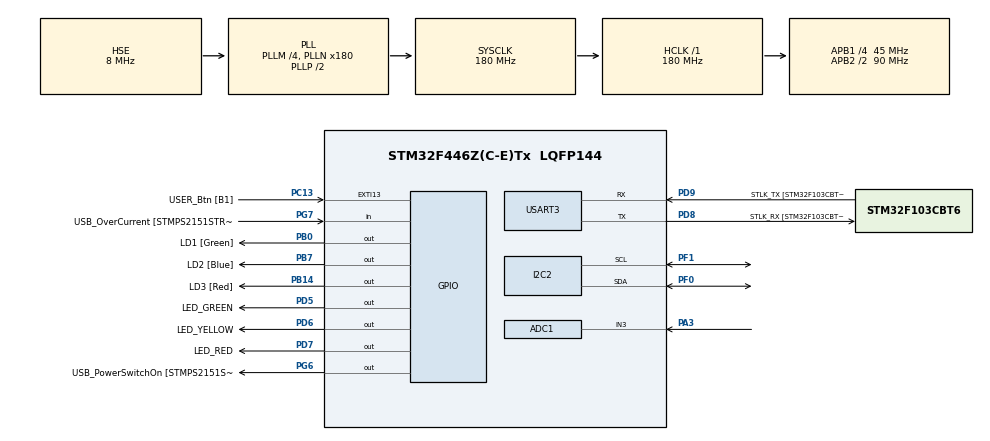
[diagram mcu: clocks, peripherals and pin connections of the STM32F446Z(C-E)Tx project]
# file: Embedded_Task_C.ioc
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ADC1.Channel-2\#ChannelRegularConversion=ADC_CHANNEL_3
ADC1.ClockPrescaler=ADC_CLOCK_SYNC_PCLK_DIV8
ADC1.ExternalTrigConv=ADC_EXTERNALTRIGCONV_T2_TRGO
ADC1.InjNumberOfConversion=0
ADC1.NbrOfConversion=1
ADC1.NbrOfConversionFlag=1
ADC1.Rank-2\#ChannelRegularConversion=1
ADC1.SamplingTime-2\#ChannelRegularConversion=ADC_SAMPLETIME_480CYCLES
ADC1.master=1
Mcu.Family=STM32F4
Mcu.Name=STM32F446Z(C-E)Tx
Mcu.Package=LQFP144
NVIC.ADC_IRQn=true\:0\:0\:false\:false\:true\:true\:true\:true
NVIC.PriorityGroup=NVIC_PRIORITYGROUP_4
NVIC.USART3_IRQn=true\:14\:0\:true\:false\:true\:true\:true\:true
PA10.GPIO_Label=USB_ID
PA10.Signal=USB_OTG_FS_ID
PA11.GPIO_Label=USB_DM
PA11.Signal=USB_OTG_FS_DM
PA12.GPIO_Label=USB_DP
PA12.Signal=USB_OTG_FS_DP
PA13.GPIO_Label=TMS
PA13.Mode=Serial_Wire
PA13.Signal=SYS_JTMS-SWDIO
PA14.GPIO_Label=TCK
PA14.Mode=Serial_Wire
PA14.Signal=SYS_JTCK-SWCLK
PA3.Signal=ADCx_IN3
PA8.GPIO_Label=USB_SOF [TP1]
PA8.Signal=USB_OTG_FS_SOF
PA9.GPIO_Label=USB_VBUS
PA9.Signal=USB_OTG_FS_VBUS
PB0.GPIO_Label=LD1 [Green]
PB0.Signal=GPIO_Output
PB14.GPIO_Label=LD3 [Red]
PB14.Signal=GPIO_Output
PB7.GPIO_Label=LD2 [Blue]
PB7.Signal=GPIO_Output
PC13.GPIO_Label=USER_Btn [B1]
PC13.Signal=GPXTI13
PC14-OSC32_IN.Mode=LSE-External-Oscillator
PC14-OSC32_IN.Signal=RCC_OSC32_IN
PC15-OSC32_OUT.Mode=LSE-External-Oscillator
PC15-OSC32_OUT.Signal=RCC_OSC32_OUT
PD5.GPIO_Label=LED_GREEN
PD5.Signal=GPIO_Output
PD6.GPIO_Label=LED_YELLOW
PD6.Signal=GPIO_Output
PD7.GPIO_Label=LED_RED
PD7.Signal=GPIO_Output
PD8.GPIO_Label=STLK_RX [STM32F103CBT6_PA3]
PD8.Mode=Asynchronous
PD8.Signal=USART3_TX
PD9.GPIO_Label=STLK_TX [STM32F103CBT6_PA2]
PD9.Mode=Asynchronous
PD9.Signal=USART3_RX
PF0.Mode=I2C
PF0.Signal=I2C2_SDA
PF1.Mode=I2C
PF1.Signal=I2C2_SCL
PG6.GPIO_Label=USB_PowerSwitchOn [STMPS2151STR_EN]
PG6.Signal=GPIO_Output
PG7.GPIO_Label=USB_OverCurrent [STMPS2151STR_FAULT]
PG7.Signal=GPIO_Input
PH0-OSC_IN.GPIO_Label=MCO [STM32F103CBT6_PA8]
PH0-OSC_IN.Mode=HSE-External-Clock-Source
PH0-OSC_IN.Signal=RCC_OSC_IN
PH1-OSC_OUT.Mode=HSE-External-Clock-Source
PH1-OSC_OUT.Signal=RCC_OSC_OUT
ProjectManager.HeapSize=0x200
ProjectManager.StackSize=0x400
ProjectManager.TargetToolchain=STM32CubeIDE
RCC.48MHZClocksFreq_Value=24000000
RCC.AHBFreq_Value=180000000
RCC.APB1CLKDivider=RCC_HCLK_DIV4
RCC.APB1Freq_Value=45000000
RCC.APB1TimFreq_Value=90000000
RCC.APB2CLKDivider=RCC_HCLK_DIV2
RCC.APB2Freq_Value=90000000
RCC.APB2TimFreq_Value=180000000
RCC.CortexFreq_Value=180000000
RCC.HCLKFreq_Value=180000000
RCC.HSE_VALUE=8000000
RCC.HSI_VALUE=16000000
RCC.PLLM=4
RCC.PLLMUL=RCC_PLL_MUL9
RCC.PLLN=180
RCC.PLLQ=7
RCC.PLLSourceVirtual=RCC_PLLSOURCE_HSE
RCC.PRESCALERUSB=RCC_USBCLKSOURCE_PLL_DIV1_5
RCC.SYSCLKFreq_VALUE=180000000
RCC.SYSCLKSource=RCC_SYSCLKSOURCE_PLLCLK
RCC.SYSCLKSourceVirtual=RCC_SYSCLKSOURCE_PLLCLK
RCC.USBFreq_Value=51428571.428571425
RCC.VCOOutputFreq_Value=360000000
SH.ADCx_IN3.0=ADC1_IN3,IN3
TIM2.Channel-PWM\ Generation1\ No\ Output=TIM_CHANNEL_1
TIM2.Period=8999
TIM2.Prescaler=0
TIM2.TIM_MasterOutputTrigger=TIM_TRGO_UPDATE
USART3.VirtualMode=VM_ASYNC
VP_TIM2_VS_no_output1.Mode=PWM Generation1 No Output
board=NUCLEO-F446ZE

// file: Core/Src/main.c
/* USER CODE BEGIN Header */
/**
  ******************************************************************************
  * @file           : main.c
  * @brief          : Main program body
  ******************************************************************************
  * @attention
  *
  * Copyright (c) 2025 STMicroelectronics.
  * All rights reserved.
  *
  * This software is licensed under terms that can be found in the LICENSE file
  * in the root directory of this software component.
  * If no LICENSE file comes with this software, it is provided AS-IS.
  *
  ******************************************************************************
  */
/* USER CODE END Header */
#include "main.h"

/* USER CODE BEGIN Includes */
#include "retarget.h"
#include "system.h"
/* USER CODE END Includes */

ADC_HandleTypeDef hadc1;

I2C_HandleTypeDef hi2c2;

TIM_HandleTypeDef htim2;

UART_HandleTypeDef huart3;

void SystemClock_Config(void);
static void MX_GPIO_Init(void);
static void MX_USART3_UART_Init(void);
static void MX_ADC1_Init(void);
static void MX_TIM2_Init(void);
static void MX_I2C2_Init(void);

int main(void)
{

  /* MCU Configuration--------------------------------------------------------*/

  /* Reset of all peripherals, Initializes the Flash interface and the Systick. */
  HAL_Init();

  /* Configure the system clock */
  SystemClock_Config();

  /* Initialize all configured peripherals */
  MX_GPIO_Init();
  MX_USART3_UART_Init();
  MX_ADC1_Init();
  MX_TIM2_Init();
  MX_I2C2_Init();
  /* USER CODE BEGIN 2 */

  RetargetInit(&huart3);

  HAL_Delay(1000);

  if (!SYSTEM_Init()) {
    //initialisation failed: wait a little to allow debug printouts to finish, then halt
    printf("*** System initialisation failed!\n");
    HAL_Delay(100);
    Error_Handler();
  }

  /* USER CODE END 2 */

  /* Infinite loop */
  while (1)
  {

    /* USER CODE BEGIN 3 */

    //perform system loop updates
    SYSTEM_LoopUpdate();
  }
  /* USER CODE END 3 */
}

void SystemClock_Config(void)
{
  RCC_OscInitTypeDef RCC_OscInitStruct = {0};
  RCC_ClkInitTypeDef RCC_ClkInitStruct = {0};

  /** Configure the main internal regulator output voltage
  */
  __HAL_RCC_PWR_CLK_ENABLE();
  __HAL_PWR_VOLTAGESCALING_CONFIG(PWR_REGULATOR_VOLTAGE_SCALE1);

  /** Initializes the RCC Oscillators according to the specified parameters
  * in the RCC_OscInitTypeDef structure.
  */
  RCC_OscInitStruct.OscillatorType = RCC_OSCILLATORTYPE_HSE;
  RCC_OscInitStruct.HSEState = RCC_HSE_BYPASS;
  RCC_OscInitStruct.PLL.PLLState = RCC_PLL_ON;
  RCC_OscInitStruct.PLL.PLLSource = RCC_PLLSOURCE_HSE;
  RCC_OscInitStruct.PLL.PLLM = 4;
  RCC_OscInitStruct.PLL.PLLN = 180;
  RCC_OscInitStruct.PLL.PLLP = RCC_PLLP_DIV2;
  RCC_OscInitStruct.PLL.PLLQ = 7;
  RCC_OscInitStruct.PLL.PLLR = 2;
  if (HAL_RCC_OscConfig(&RCC_OscInitStruct) != HAL_OK)
  {
    Error_Handler();
  }

  /** Activate the Over-Drive mode
  */
  if (HAL_PWREx_EnableOverDrive() != HAL_OK)
  {
    Error_Handler();
  }

  /** Initializes the CPU, AHB and APB buses clocks
  */
  RCC_ClkInitStruct.ClockType = RCC_CLOCKTYPE_HCLK|RCC_CLOCKTYPE_SYSCLK
                              |RCC_CLOCKTYPE_PCLK1|RCC_CLOCKTYPE_PCLK2;
  RCC_ClkInitStruct.SYSCLKSource = RCC_SYSCLKSOURCE_PLLCLK;
  RCC_ClkInitStruct.AHBCLKDivider = RCC_SYSCLK_DIV1;
  RCC_ClkInitStruct.APB1CLKDivider = RCC_HCLK_DIV4;
  RCC_ClkInitStruct.APB2CLKDivider = RCC_HCLK_DIV2;

  if (HAL_RCC_ClockConfig(&RCC_ClkInitStruct, FLASH_LATENCY_5) != HAL_OK)
  {
    Error_Handler();
  }
}

static void MX_ADC1_Init(void)
{

  ADC_ChannelConfTypeDef sConfig = {0};

  /** Configure the global features of the ADC (Clock, Resolution, Data Alignment and number of conversion)
  */
  hadc1.Instance = ADC1;
  hadc1.Init.ClockPrescaler = ADC_CLOCK_SYNC_PCLK_DIV8;
  hadc1.Init.Resolution = ADC_RESOLUTION_12B;
  hadc1.Init.ScanConvMode = DISABLE;
  hadc1.Init.ContinuousConvMode = DISABLE;
  hadc1.Init.DiscontinuousConvMode = DISABLE;
  hadc1.Init.ExternalTrigConvEdge = ADC_EXTERNALTRIGCONVEDGE_RISING;
  hadc1.Init.ExternalTrigConv = ADC_EXTERNALTRIGCONV_T2_TRGO;
  hadc1.Init.DataAlign = ADC_DATAALIGN_RIGHT;
  hadc1.Init.NbrOfConversion = 1;
  hadc1.Init.DMAContinuousRequests = DISABLE;
  hadc1.Init.EOCSelection = ADC_EOC_SINGLE_CONV;
  if (HAL_ADC_Init(&hadc1) != HAL_OK)
  {
    Error_Handler();
  }

  /** Configure for the selected ADC regular channel its corresponding rank in the sequencer and its sample time.
  */
  sConfig.Channel = ADC_CHANNEL_3;
  sConfig.Rank = 1;
  sConfig.SamplingTime = ADC_SAMPLETIME_480CYCLES;
  if (HAL_ADC_ConfigChannel(&hadc1, &sConfig) != HAL_OK)
  {
    Error_Handler();
  }

}

static void MX_I2C2_Init(void)
{

  hi2c2.Instance = I2C2;
  hi2c2.Init.ClockSpeed = 100000;
  hi2c2.Init.DutyCycle = I2C_DUTYCYCLE_2;
  hi2c2.Init.OwnAddress1 = 0;
  hi2c2.Init.AddressingMode = I2C_ADDRESSINGMODE_7BIT;
  hi2c2.Init.DualAddressMode = I2C_DUALADDRESS_DISABLE;
  hi2c2.Init.OwnAddress2 = 0;
  hi2c2.Init.GeneralCallMode = I2C_GENERALCALL_DISABLE;
  hi2c2.Init.NoStretchMode = I2C_NOSTRETCH_DISABLE;
  if (HAL_I2C_Init(&hi2c2) != HAL_OK)
  {
    Error_Handler();
  }

}

static void MX_TIM2_Init(void)
{

  TIM_MasterConfigTypeDef sMasterConfig = {0};
  TIM_OC_InitTypeDef sConfigOC = {0};

  htim2.Instance = TIM2;
  htim2.Init.Prescaler = 0;
  htim2.Init.CounterMode = TIM_COUNTERMODE_UP;
  htim2.Init.Period = 8999;
  htim2.Init.ClockDivision = TIM_CLOCKDIVISION_DIV1;
  htim2.Init.AutoReloadPreload = TIM_AUTORELOAD_PRELOAD_DISABLE;
  if (HAL_TIM_PWM_Init(&htim2) != HAL_OK)
  {
    Error_Handler();
  }
  sMasterConfig.MasterOutputTrigger = TIM_TRGO_UPDATE;
  sMasterConfig.MasterSlaveMode = TIM_MASTERSLAVEMODE_DISABLE;
  if (HAL_TIMEx_MasterConfigSynchronization(&htim2, &sMasterConfig) != HAL_OK)
  {
    Error_Handler();
  }
  sConfigOC.OCMode = TIM_OCMODE_PWM1;
  sConfigOC.Pulse = 0;
  sConfigOC.OCPolarity = TIM_OCPOLARITY_HIGH;
  sConfigOC.OCFastMode = TIM_OCFAST_DISABLE;
  if (HAL_TIM_PWM_ConfigChannel(&htim2, &sConfigOC, TIM_CHANNEL_1) != HAL_OK)
  {
    Error_Handler();
  }

}

static void MX_USART3_UART_Init(void)
{

  huart3.Instance = USART3;
  huart3.Init.BaudRate = 115200;
  huart3.Init.WordLength = UART_WORDLENGTH_8B;
  huart3.Init.StopBits = UART_STOPBITS_1;
  huart3.Init.Parity = UART_PARITY_NONE;
  huart3.Init.Mode = UART_MODE_TX_RX;
  huart3.Init.HwFlowCtl = UART_HWCONTROL_NONE;
  huart3.Init.OverSampling = UART_OVERSAMPLING_16;
  if (HAL_UART_Init(&huart3) != HAL_OK)
  {
    Error_Handler();
  }

}

static void MX_GPIO_Init(void)
{
  GPIO_InitTypeDef GPIO_InitStruct = {0};

  /* GPIO Ports Clock Enable */
  __HAL_RCC_GPIOC_CLK_ENABLE();
  __HAL_RCC_GPIOF_CLK_ENABLE();
  __HAL_RCC_GPIOH_CLK_ENABLE();
  __HAL_RCC_GPIOA_CLK_ENABLE();
  __HAL_RCC_GPIOB_CLK_ENABLE();
  __HAL_RCC_GPIOD_CLK_ENABLE();
  __HAL_RCC_GPIOG_CLK_ENABLE();

  /*Configure GPIO pin Output Level */
  HAL_GPIO_WritePin(GPIOB, LD1_Pin|LD3_Pin|LD2_Pin, GPIO_PIN_RESET);

  /*Configure GPIO pin Output Level */
  HAL_GPIO_WritePin(USB_PowerSwitchOn_GPIO_Port, USB_PowerSwitchOn_Pin, GPIO_PIN_RESET);

  /*Configure GPIO pin Output Level */
  HAL_GPIO_WritePin(GPIOD, LED_GREEN_Pin|LED_YELLOW_Pin|LED_RED_Pin, GPIO_PIN_RESET);

  /*Configure GPIO pin : USER_Btn_Pin */
  GPIO_InitStruct.Pin = USER_Btn_Pin;
  GPIO_InitStruct.Mode = GPIO_MODE_IT_RISING;
  GPIO_InitStruct.Pull = GPIO_NOPULL;
  HAL_GPIO_Init(USER_Btn_GPIO_Port, &GPIO_InitStruct);

  /*Configure GPIO pins : LD1_Pin LD3_Pin LD2_Pin */
  GPIO_InitStruct.Pin = LD1_Pin|LD3_Pin|LD2_Pin;
  GPIO_InitStruct.Mode = GPIO_MODE_OUTPUT_PP;
  GPIO_InitStruct.Pull = GPIO_NOPULL;
  GPIO_InitStruct.Speed = GPIO_SPEED_FREQ_LOW;
  HAL_GPIO_Init(GPIOB, &GPIO_InitStruct);

  /*Configure GPIO pin : USB_PowerSwitchOn_Pin */
  GPIO_InitStruct.Pin = USB_PowerSwitchOn_Pin;
  GPIO_InitStruct.Mode = GPIO_MODE_OUTPUT_PP;
  GPIO_InitStruct.Pull = GPIO_NOPULL;
  GPIO_InitStruct.Speed = GPIO_SPEED_FREQ_LOW;
  HAL_GPIO_Init(USB_PowerSwitchOn_GPIO_Port, &GPIO_InitStruct);

  /*Configure GPIO pin : USB_OverCurrent_Pin */
  GPIO_InitStruct.Pin = USB_OverCurrent_Pin;
  GPIO_InitStruct.Mode = GPIO_MODE_INPUT;
  GPIO_InitStruct.Pull = GPIO_NOPULL;
  HAL_GPIO_Init(USB_OverCurrent_GPIO_Port, &GPIO_InitStruct);

  /*Configure GPIO pins : USB_SOF_Pin USB_ID_Pin USB_DM_Pin USB_DP_Pin */
  GPIO_InitStruct.Pin = USB_SOF_Pin|USB_ID_Pin|USB_DM_Pin|USB_DP_Pin;
  GPIO_InitStruct.Mode = GPIO_MODE_AF_PP;
  GPIO_InitStruct.Pull = GPIO_NOPULL;
  GPIO_InitStruct.Speed = GPIO_SPEED_FREQ_VERY_HIGH;
  GPIO_InitStruct.Alternate = GPIO_AF10_OTG_FS;
  HAL_GPIO_Init(GPIOA, &GPIO_InitStruct);

  /*Configure GPIO pin : USB_VBUS_Pin */
  GPIO_InitStruct.Pin = USB_VBUS_Pin;
  GPIO_InitStruct.Mode = GPIO_MODE_INPUT;
  GPIO_InitStruct.Pull = GPIO_NOPULL;
  HAL_GPIO_Init(USB_VBUS_GPIO_Port, &GPIO_InitStruct);

  /*Configure GPIO pins : LED_GREEN_Pin LED_YELLOW_Pin LED_RED_Pin */
  GPIO_InitStruct.Pin = LED_GREEN_Pin|LED_YELLOW_Pin|LED_RED_Pin;
  GPIO_InitStruct.Mode = GPIO_MODE_OUTPUT_PP;
  GPIO_InitStruct.Pull = GPIO_NOPULL;
  GPIO_InitStruct.Speed = GPIO_SPEED_FREQ_LOW;
  HAL_GPIO_Init(GPIOD, &GPIO_InitStruct);

}

void Error_Handler(void)
{
  __disable_irq();
  while (1)
  {
  }
}
